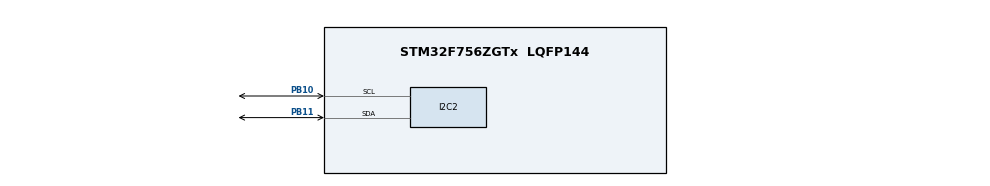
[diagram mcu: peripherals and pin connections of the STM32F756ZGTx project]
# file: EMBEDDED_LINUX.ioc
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I2C2.OwnAddress=0x30
Mcu.Family=STM32F7
Mcu.Name=STM32F756ZGTx
Mcu.Package=LQFP144
NVIC.I2C2_ER_IRQn=true\:0\:0\:false\:false\:true\:true\:true\:true
NVIC.I2C2_EV_IRQn=true\:0\:0\:false\:false\:true\:true\:true\:true
NVIC.PriorityGroup=NVIC_PRIORITYGROUP_4
PB10.GPIO_Pu=GPIO_PULLUP
PB10.Mode=I2C
PB10.Signal=I2C2_SCL
PB11.GPIO_Pu=GPIO_PULLUP
PB11.Mode=I2C
PB11.Signal=I2C2_SDA
ProjectManager.HeapSize=0x200
ProjectManager.StackSize=0x400
ProjectManager.TargetToolchain=STM32CubeIDE
RCC.HSE_VALUE=25000000
RCC.HSI_VALUE=16000000
RCC.LSE_VALUE=32768
RCC.USBFreq_Value=96000000
RCC.VCOOutputFreq_Value=192000000
VP_RTC_VS_RTC_Activate.Mode=RTC_Enabled
board=custom

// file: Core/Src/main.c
/* USER CODE BEGIN Header */
/**
  ******************************************************************************
  * @file           : main.c
  * @brief          : Main program body
  ******************************************************************************
  */
/* USER CODE END Header */
#include "main.h"
#include "i2c.h"
#include "rtc.h"
#include "gpio.h"

/* USER CODE BEGIN Includes */
#include "rtg.h"
#include <time.h>
/* USER CODE END Includes */

void SystemClock_Config(void);

int main(void)
{

  /* MCU Configuration--------------------------------------------------------*/

  /* Reset of all peripherals, Initializes the Flash interface and the Systick. */
  HAL_Init();

  /* Configure the system clock */
  SystemClock_Config();

  /* Initialize all configured peripherals */
  MX_GPIO_Init();
  MX_I2C2_Init();
  MX_RTC_Init();
  /* USER CODE BEGIN 2 */

  GPS_Emulator_Init();
  GPS_Emulator_Start_Listening(&hi2c2);
  /* USER CODE END 2 */

  /* Infinite loop */
  while (1)
  {

    /* USER CODE BEGIN 3 */
	  GPS_Emulator_Task();

  }
  /* USER CODE END 3 */
}

void SystemClock_Config(void)
{
  RCC_OscInitTypeDef RCC_OscInitStruct = {0};
  RCC_ClkInitTypeDef RCC_ClkInitStruct = {0};

  /** Configure the main internal regulator output voltage
  */
  __HAL_RCC_PWR_CLK_ENABLE();
  __HAL_PWR_VOLTAGESCALING_CONFIG(PWR_REGULATOR_VOLTAGE_SCALE3);

  /** Initializes the RCC Oscillators according to the specified parameters
  * in the RCC_OscInitTypeDef structure.
  */
  RCC_OscInitStruct.OscillatorType = RCC_OSCILLATORTYPE_HSI|RCC_OSCILLATORTYPE_LSI;
  RCC_OscInitStruct.HSIState = RCC_HSI_ON;
  RCC_OscInitStruct.HSICalibrationValue = RCC_HSICALIBRATION_DEFAULT;
  RCC_OscInitStruct.LSIState = RCC_LSI_ON;
  RCC_OscInitStruct.PLL.PLLState = RCC_PLL_NONE;
  if (HAL_RCC_OscConfig(&RCC_OscInitStruct) != HAL_OK)
  {
    Error_Handler();
  }

  /** Initializes the CPU, AHB and APB buses clocks
  */
  RCC_ClkInitStruct.ClockType = RCC_CLOCKTYPE_HCLK|RCC_CLOCKTYPE_SYSCLK
                              |RCC_CLOCKTYPE_PCLK1|RCC_CLOCKTYPE_PCLK2;
  RCC_ClkInitStruct.SYSCLKSource = RCC_SYSCLKSOURCE_HSI;
  RCC_ClkInitStruct.AHBCLKDivider = RCC_SYSCLK_DIV1;
  RCC_ClkInitStruct.APB1CLKDivider = RCC_HCLK_DIV1;
  RCC_ClkInitStruct.APB2CLKDivider = RCC_HCLK_DIV1;

  if (HAL_RCC_ClockConfig(&RCC_ClkInitStruct, FLASH_LATENCY_0) != HAL_OK)
  {
    Error_Handler();
  }
}

void Error_Handler(void)
{
  __disable_irq();
  while (1)
  {
  }
}
